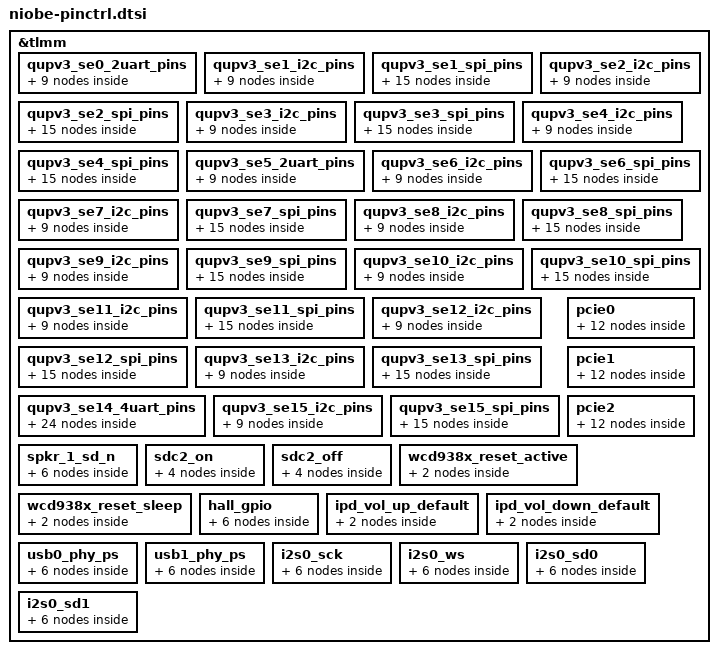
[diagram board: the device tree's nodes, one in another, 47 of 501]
&tlmm {
	qupv3_se0_2uart_pins: qupv3_se0_2uart_pins {
		qupv3_se0_2uart_tx_active: qupv3_se0_2uart_tx_active {
			mux {
				pins = "gpio54";
				function = "qup1_se0_l2";
			};

			config {
				pins = "gpio54";
				drive-strength = <2>;
				bias-disable;
			};
		};

		qupv3_se0_2uart_rx_active: qupv3_se0_2uart_rx_active {
			mux {
				pins = "gpio55";
				function = "qup1_se0_l3";
			};

			config {
				pins = "gpio55";
				drive-strength = <2>;
				bias-disable;
			};
		};

		qupv3_se0_2uart_sleep: qupv3_se0_2uart_sleep {
			mux {
				pins = "gpio54", "gpio55";
				function = "gpio";
			};

			config {
				pins = "gpio54", "gpio55";
				drive-strength = <2>;
				bias-pull-down;
			};
		};
	};

	qupv3_se1_i2c_pins: qupv3_se1_i2c_pins {
		qupv3_se1_i2c_sda_active: qupv3_se1_i2c_sda_active {
			mux {
				pins = "gpio56";
				function = "qup1_se1_l0";
			};

			config {
				pins = "gpio56";
				drive-strength = <2>;
				bias-pull-up;
			};
		};

		qupv3_se1_i2c_scl_active: qupv3_se1_i2c_scl_active {
			mux {
				pins = "gpio57";
				function = "qup1_se1_l1";
			};

			config {
				pins = "gpio57";
				drive-strength = <2>;
				bias-pull-up;
			};
		};

		qupv3_se1_i2c_sleep: qupv3_se1_i2c_sleep {
			mux {
				pins = "gpio56", "gpio57";
				function = "gpio";
			};

			config {
				pins = "gpio56", "gpio57";
				drive-strength = <2>;
				bias-disable;
			};
		};
	};

	qupv3_se1_spi_pins: qupv3_se1_spi_pins {
		qupv3_se1_spi_miso_active: qupv3_se1_spi_miso_active {
			mux {
				pins = "gpio56";
				function = "qup1_se1_l0";
			};

			config {
				pins = "gpio56";
				drive-strength = <6>;
				bias-disable;
			};
		};

		qupv3_se1_spi_mosi_active: qupv3_se1_spi_mosi_active {
			mux {
				pins = "gpio57";
				function = "qup1_se1_l1";
			};

			config {
				pins = "gpio57";
				drive-strength = <6>;
				bias-disable;
			};
		};

		qupv3_se1_spi_clk_active: qupv3_se1_spi_clk_active {
			mux {
				pins = "gpio58";
				function = "qup1_se1_l2";
			};

			config {
				pins = "gpio58";
				drive-strength = <6>;
				bias-disable;
			};
		};

		qupv3_se1_spi_cs_active: qupv3_se1_spi_cs_active {
			mux {
				pins = "gpio59";
				function = "qup1_se1_l3";
			};

			config {
				pins = "gpio59";
				drive-strength = <6>;
				bias-disable;
			};
		};

		qupv3_se1_spi_sleep: qupv3_se1_spi_sleep {
			mux {
				pins = "gpio56", "gpio57",
					"gpio58", "gpio59";
				function = "gpio";
			};

			config {
				pins = "gpio56", "gpio57",
					"gpio58", "gpio59";
				drive-strength = <2>;
				bias-disable;
			};
		};
	};

	qupv3_se2_i2c_pins: qupv3_se2_i2c_pins {
		qupv3_se2_i2c_sda_active: qupv3_se2_i2c_sda_active {
			mux {
				pins = "gpio63";
				function = "qup1_se2_l0";
			};

			config {
				pins = "gpio63";
				drive-strength = <2>;
				bias-pull-up;
			};
		};

		qupv3_se2_i2c_scl_active: qupv3_se2_i2c_scl_active {
			mux {
				pins = "gpio64";
				function = "qup1_se2_l1";
			};

			config {
				pins = "gpio64";
				drive-strength = <2>;
				bias-pull-up;
			};
		};

		qupv3_se2_i2c_sleep: qupv3_se2_i2c_sleep {
			mux {
				pins = "gpio63", "gpio64";
				function = "gpio";
			};

			config {
				pins = "gpio63", "gpio64";
				drive-strength = <2>;
				bias-disable;
			};
		};
	};

	qupv3_se2_spi_pins: qupv3_se2_spi_pins {
		qupv3_se2_spi_miso_active: qupv3_se2_spi_miso_active {
			mux {
				pins = "gpio63";
				function = "qup1_se2_l0";
			};

			config {
				pins = "gpio63";
				drive-strength = <6>;
				bias-disable;
			};
		};

		qupv3_se2_spi_mosi_active: qupv3_se2_spi_mosi_active {
			mux {
				pins = "gpio64";
				function = "qup1_se2_l1";
			};

			config {
				pins = "gpio64";
				drive-strength = <6>;
				bias-disable;
			};
		};

		qupv3_se2_spi_clk_active: qupv3_se2_spi_clk_active {
			mux {
				pins = "gpio65";
				function = "qup1_se2_l2";
			};

			config {
				pins = "gpio65";
				drive-strength = <6>;
				bias-disable;
			};
		};

		qupv3_se2_spi_cs_active: qupv3_se2_spi_cs_active {
			mux {
				pins = "gpio66";
				function = "qup1_se2_l3";
			};

			config {
				pins = "gpio66";
				drive-strength = <6>;
				bias-disable;
			};
		};

		qupv3_se2_spi_sleep: qupv3_se2_spi_sleep {
			mux {
				pins = "gpio63", "gpio64",
					"gpio65", "gpio66";
				function = "gpio";
			};

			config {
				pins = "gpio63", "gpio64",
					"gpio65", "gpio66";
				drive-strength = <2>;
				bias-disable;
			};
		};
	};

	qupv3_se3_i2c_pins: qupv3_se3_i2c_pins {
		qupv3_se3_i2c_sda_active: qupv3_se3_i2c_sda_active {
			mux {
				pins = "gpio67";
				function = "qup1_se3_l0";
			};

			config {
				pins = "gpio67";
				drive-strength = <2>;
				bias-pull-up;
			};
		};

		qupv3_se3_i2c_scl_active: qupv3_se3_i2c_scl_active {
			mux {
				pins = "gpio68";
				function = "qup1_se3_l1";
			};

			config {
				pins = "gpio68";
				drive-strength = <2>;
				bias-pull-up;
			};
		};

		qupv3_se3_i2c_sleep: qupv3_se3_i2c_sleep {
			mux {
				pins = "gpio67", "gpio68";
				function = "gpio";
			};

			config {
				pins = "gpio67", "gpio68";
				drive-strength = <2>;
				bias-disable;
			};
		};
	};

	qupv3_se3_spi_pins: qupv3_se3_spi_pins {
		qupv3_se3_spi_miso_active: qupv3_se3_spi_miso_active {
			mux {
				pins = "gpio67";
				function = "qup1_se3_l0";
			};

			config {
				pins = "gpio67";
				drive-strength = <6>;
				bias-disable;
			};
		};

		qupv3_se3_spi_mosi_active: qupv3_se3_spi_mosi_active {
			mux {
				pins = "gpio68";
				function = "qup1_se3_l1";
			};

			config {
				pins = "gpio68";
				drive-strength = <6>;
				bias-disable;
			};
		};

		qupv3_se3_spi_clk_active: qupv3_se3_spi_clk_active {
			mux {
				pins = "gpio69";
				function = "qup1_se3_l2";
			};

			config {
				pins = "gpio69";
				drive-strength = <6>;
				bias-disable;
			};
		};

		qupv3_se3_spi_cs_active: qupv3_se3_spi_cs_active {
			mux {
				pins = "gpio70";
				function = "qup1_se3_l3";
			};

			config {
				pins = "gpio70";
				drive-strength = <6>;
				bias-disable;
			};
		};

		qupv3_se3_spi_sleep: qupv3_se3_spi_sleep {
			mux {
				pins = "gpio67", "gpio68",
					"gpio69", "gpio70";
				function = "gpio";
			};

			config {
				pins = "gpio67", "gpio68",
					"gpio69", "gpio70";
				drive-strength = <2>;
				bias-disable;
			};
		};
	};

	qupv3_se4_i2c_pins: qupv3_se4_i2c_pins {
		qupv3_se4_i2c_sda_active: qupv3_se4_i2c_sda_active {
			mux {
				pins = "gpio0";
				function = "qup2_se0_l0";
			};

			config {
				pins = "gpio0";
				drive-strength = <2>;
				bias-pull-up;
			};
		};

		qupv3_se4_i2c_scl_active: qupv3_se4_i2c_scl_active {
			mux {
				pins = "gpio1";
				function = "qup2_se0_l1";
			};

			config {
				pins = "gpio1";
				drive-strength = <2>;
				bias-pull-up;
			};
		};

		qupv3_se4_i2c_sleep: qupv3_se4_i2c_sleep {
			mux {
				pins = "gpio0", "gpio1";
				function = "gpio";
			};

			config {
				pins = "gpio0", "gpio1";
				drive-strength = <2>;
				bias-disable;
			};
		};
	};

	qupv3_se4_spi_pins: qupv3_se4_spi_pins {
		qupv3_se4_spi_miso_active: qupv3_se4_spi_miso_active {
			mux {
				pins = "gpio0";
				function = "qup2_se0_l0";
			};

			config {
				pins = "gpio0";
				drive-strength = <6>;
				bias-disable;
			};
		};

		qupv3_se4_spi_mosi_active: qupv3_se4_spi_mosi_active {
			mux {
				pins = "gpio1";
				function = "qup2_se0_l1";
			};

			config {
				pins = "gpio1";
				drive-strength = <6>;
				bias-disable;
			};
		};

		qupv3_se4_spi_clk_active: qupv3_se4_spi_clk_active {
			mux {
				pins = "gpio2";
				function = "qup2_se0_l2";
			};

			config {
				pins = "gpio2";
				drive-strength = <6>;
				bias-disable;
			};
		};

		qupv3_se4_spi_cs_active: qupv3_se4_spi_cs_active {
			mux {
				pins = "gpio3";
				function = "qup2_se0_l3";
			};

			config {
				pins = "gpio3";
				drive-strength = <6>;
				bias-disable;
			};
		};

		qupv3_se4_spi_sleep: qupv3_se4_spi_sleep {
			mux {
				pins = "gpio0", "gpio1",
					"gpio2", "gpio3";
				function = "gpio";
			};

			config {
				pins = "gpio0", "gpio1",
					"gpio2", "gpio3";
				drive-strength = <2>;
				bias-disable;
			};
		};
	};

	qupv3_se5_2uart_pins: qupv3_se5_2uart_pins {
		qupv3_se5_2uart_tx_active: qupv3_se5_2uart_tx_active {
			mux {
				pins = "gpio6";
				function = "qup2_se1_l2";
			};

			config {
				pins = "gpio6";
				drive-strength = <2>;
				bias-disable;
			};
		};

		qupv3_se5_2uart_rx_active: qupv3_se5_2uart_rx_active {
			mux {
				pins = "gpio7";
				function = "qup2_se1_l3";
			};

			config {
				pins = "gpio7";
				drive-strength = <2>;
				bias-disable;
			};
		};

		qupv3_se5_2uart_sleep: qupv3_se5_2uart_sleep {
			mux {
				pins = "gpio6", "gpio7";
				function = "gpio";
			};

			config {
				pins = "gpio6", "gpio7";
				drive-strength = <2>;
				bias-pull-down;
			};
		};
	};

	qupv3_se6_i2c_pins: qupv3_se6_i2c_pins {
		qupv3_se6_i2c_sda_active: qupv3_se6_i2c_sda_active {
			mux {
				pins = "gpio8";
				function = "qup2_se2_l0";
			};

			config {
				pins = "gpio8";
				drive-strength = <2>;
				bias-pull-up;
			};
		};

		qupv3_se6_i2c_scl_active: qupv3_se6_i2c_scl_active {
			mux {
				pins = "gpio9";
				function = "qup2_se2_l1";
			};

			config {
				pins = "gpio9";
				drive-strength = <2>;
				bias-pull-up;
			};
		};

		qupv3_se6_i2c_sleep: qupv3_se6_i2c_sleep {
			mux {
				pins = "gpio8", "gpio9";
				function = "gpio";
			};

			config {
				pins = "gpio8", "gpio9";
				drive-strength = <2>;
				bias-disable;
			};
		};
	};

	qupv3_se6_spi_pins: qupv3_se6_spi_pins {
		qupv3_se6_spi_miso_active: qupv3_se6_spi_miso_active {
			mux {
				pins = "gpio8";
				function = "qup2_se2_l0";
			};

			config {
				pins = "gpio8";
				drive-strength = <6>;
				bias-disable;
			};
		};

		qupv3_se6_spi_mosi_active: qupv3_se6_spi_mosi_active {
			mux {
				pins = "gpio9";
				function = "qup2_se2_l1";
			};

			config {
				pins = "gpio9";
				drive-strength = <6>;
				bias-disable;
			};
		};

		qupv3_se6_spi_clk_active: qupv3_se6_spi_clk_active {
			mux {
				pins = "gpio10";
				function = "qup2_se2_l2";
			};

			config {
				pins = "gpio10";
				drive-strength = <6>;
				bias-disable;
			};
		};

		qupv3_se6_spi_cs_active: qupv3_se6_spi_cs_active {
			mux {
				pins = "gpio11";
				function = "qup2_se2_l3_mira";
			};

			config {
				pins = "gpio11";
				drive-strength = <6>;
				bias-disable;
			};
		};

		qupv3_se6_spi_sleep: qupv3_se6_spi_sleep {
			mux {
				pins = "gpio8", "gpio9",
					"gpio10", "gpio11";
				function = "gpio";
			};

			config {
				pins = "gpio8", "gpio9",
					"gpio10", "gpio11";
				drive-strength = <2>;
				bias-disable;
			};
		};
	};

	qupv3_se7_i2c_pins: qupv3_se7_i2c_pins {
		qupv3_se7_i2c_sda_active: qupv3_se7_i2c_sda_active {
			mux {
				pins = "gpio12";
				function = "qup2_se3_l0";
			};

			config {
				pins = "gpio12";
				drive-strength = <2>;
				bias-pull-up;
			};
		};

		qupv3_se7_i2c_scl_active: qupv3_se7_i2c_scl_active {
			mux {
				pins = "gpio13";
				function = "qup2_se3_l1";
			};

			config {
				pins = "gpio13";
				drive-strength = <2>;
				bias-pull-up;
			};
		};

		qupv3_se7_i2c_sleep: qupv3_se7_i2c_sleep {
			mux {
				pins = "gpio12", "gpio13";
				function = "gpio";
			};

			config {
				pins = "gpio12", "gpio13";
				drive-strength = <2>;
				bias-disable;
			};
		};
	};

	qupv3_se7_spi_pins: qupv3_se7_spi_pins {
		qupv3_se7_spi_miso_active: qupv3_se7_spi_miso_active {
			mux {
				pins = "gpio12";
				function = "qup2_se3_l0";
			};

			config {
				pins = "gpio12";
				drive-strength = <6>;
				bias-disable;
			};
		};

		qupv3_se7_spi_mosi_active: qupv3_se7_spi_mosi_active {
			mux {
				pins = "gpio13";
				function = "qup2_se3_l1";
			};

			config {
				pins = "gpio13";
				drive-strength = <6>;
				bias-disable;
			};
		};

		qupv3_se7_spi_clk_active: qupv3_se7_spi_clk_active {
			mux {
				pins = "gpio14";
				function = "qup2_se2_l2";
			};

			config {
				pins = "gpio14";
				drive-strength = <6>;
				bias-disable;
			};
		};

		qupv3_se7_spi_cs_active: qupv3_se7_spi_cs_active {
			mux {
				pins = "gpio15";
				function = "qup2_se3_l3";
			};

			config {
				pins = "gpio15";
				drive-strength = <6>;
				bias-disable;
			};
		};

		qupv3_se7_spi_sleep: qupv3_se7_spi_sleep {
			mux {
				pins = "gpio12", "gpio13",
					"gpio14", "gpio15";
				function = "gpio";
			};

			config {
				pins = "gpio12", "gpio13",
					"gpio14", "gpio15";
				drive-strength = <2>;
				bias-disable;
			};
		};
	};

	qupv3_se8_i2c_pins: qupv3_se8_i2c_pins {
		qupv3_se8_i2c_sda_active: qupv3_se8_i2c_sda_active {
			mux {
				pins = "gpio16";
				function = "qup2_se4_l0";
			};

			config {
				pins = "gpio16";
				drive-strength = <2>;
				bias-pull-up;
			};
		};

		qupv3_se8_i2c_scl_active: qupv3_se8_i2c_scl_active {
			mux {
				pins = "gpio17";
				function = "qup2_se4_l1";
			};

			config {
				pins = "gpio17";
				drive-strength = <2>;
				bias-pull-up;
			};
		};

		qupv3_se8_i2c_sleep: qupv3_se8_i2c_sleep {
			mux {
				pins = "gpio16", "gpio17";
				function = "gpio";
			};

			config {
				pins = "gpio16", "gpio17";
				drive-strength = <2>;
				bias-disable;
			};
		};
	};

	qupv3_se8_spi_pins: qupv3_se8_spi_pins {
		qupv3_se8_spi_miso_active: qupv3_se8_spi_miso_active {
			mux {
				pins = "gpio16";
				function = "qup2_se4_l0";
			};

			config {
				pins = "gpio16";
				drive-strength = <6>;
				bias-disable;
			};
		};

		qupv3_se8_spi_mosi_active: qupv3_se8_spi_mosi_active {
			mux {
				pins = "gpio17";
				function = "qup2_se4_l1";
			};

			config {
				pins = "gpio17";
				drive-strength = <6>;
				bias-disable;
			};
		};

		qupv3_se8_spi_clk_active: qupv3_se8_spi_clk_active {
			mux {
				pins = "gpio18";
				function = "qup2_se4_l2";
			};

			config {
				pins = "gpio18";
				drive-strength = <6>;
				bias-disable;
			};
		};

		qupv3_se8_spi_cs_active: qupv3_se8_spi_cs_active {
			mux {
				pins = "gpio19";
				function = "qup2_se4_l3";
			};

			config {
				pins = "gpio19";
				drive-strength = <6>;
				bias-disable;
			};
		};

		qupv3_se8_spi_sleep: qupv3_se8_spi_sleep {
			mux {
				pins = "gpio16", "gpio17",
					"gpio18", "gpio19";
				function = "gpio";
			};

			config {
				pins = "gpio16", "gpio17",
					"gpio18", "gpio19";
				drive-strength = <2>;
				bias-disable;
			};
		};
	};

	qupv3_se9_i2c_pins: qupv3_se9_i2c_pins {
		qupv3_se9_i2c_sda_active: qupv3_se9_i2c_sda_active {
			mux {
				pins = "gpio23";
				function = "qup2_se5_l0";
			};

			config {
				pins = "gpio23";
				drive-strength = <2>;
				bias-pull-up;
			};
		};

		qupv3_se9_i2c_scl_active: qupv3_se9_i2c_scl_active {
			mux {
				pins = "gpio24";
				function = "qup2_se5_l1";
			};

			config {
				pins = "gpio24";
				drive-strength = <2>;
				bias-pull-up;
			};
		};

		qupv3_se9_i2c_sleep: qupv3_se9_i2c_sleep {
			mux {
				pins = "gpio23", "gpio24";
				function = "gpio";
			};

			config {
				pins = "gpio23", "gpio24";
				drive-strength = <2>;
				bias-disable;
			};
		};
	};

	qupv3_se9_spi_pins: qupv3_se9_spi_pins {
		qupv3_se9_spi_miso_active: qupv3_se9_spi_miso_active {
			mux {
				pins = "gpio23";
				function = "qup2_se5_l0";
			};

			config {
				pins = "gpio23";
				drive-strength = <6>;
				bias-disable;
			};
		};

		qupv3_se9_spi_mosi_active: qupv3_se9_spi_mosi_active {
			mux {
				pins = "gpio24";
				function = "qup2_se5_l1";
			};

			config {
				pins = "gpio24";
				drive-strength = <6>;
				bias-disable;
			};
		};

		qupv3_se9_spi_clk_active: qupv3_se9_spi_clk_active {
			mux {
				pins = "gpio25";
				function = "qup2_se5_l2";
			};

			config {
				pins = "gpio25";
				drive-strength = <6>;
				bias-disable;
			};
		};

		qupv3_se9_spi_cs_active: qupv3_se9_spi_cs_active {
			mux {
				pins = "gpio26";
				function = "qup2_se5_l3_mira";
			};

			config {
				pins = "gpio26";
				drive-strength = <6>;
				bias-disable;
			};
		};

		qupv3_se9_spi_sleep: qupv3_se9_spi_sleep {
			mux {
				pins = "gpio23", "gpio24",
					"gpio25", "gpio26";
				function = "gpio";
			};

			config {
				pins = "gpio23", "gpio24",
					"gpio25", "gpio26";
				drive-strength = <2>;
				bias-disable;
			};
		};
	};

	qupv3_se10_i2c_pins: qupv3_se10_i2c_pins {
		qupv3_se10_i2c_sda_active: qupv3_se10_i2c_sda_active {
			mux {
				pins = "gpio27";
				function = "qup2_se6_l0";
			};

			config {
				pins = "gpio27";
				drive-strength = <2>;
				bias-pull-up;
			};
		};

		qupv3_se10_i2c_scl_active: qupv3_se10_i2c_scl_active {
			mux {
				pins = "gpio28";
				function = "qup2_se6_l1";
			};

			config {
				pins = "gpio28";
				drive-strength = <2>;
				bias-pull-up;
			};
		};

		qupv3_se10_i2c_sleep: qupv3_se10_i2c_sleep {
			mux {
				pins = "gpio27", "gpio28";
				function = "gpio";
			};

			config {
				pins = "gpio27", "gpio28";
				drive-strength = <2>;
				bias-disable;
			};
		};
	};

	qupv3_se10_spi_pins: qupv3_se10_spi_pins {
		qupv3_se10_spi_miso_active: qupv3_se10_spi_miso_active {
			mux {
				pins = "gpio27";
				function = "qup2_se6_l0";
			};

			config {
				pins = "gpio27";
				drive-strength = <6>;
				bias-disable;
			};
		};

		qupv3_se10_spi_mosi_active: qupv3_se10_spi_mosi_active {
			mux {
				pins = "gpio28";
				function = "qup2_se6_l1";
			};

			config {
				pins = "gpio28";
				drive-strength = <6>;
				bias-disable;
			};
		};

		qupv3_se10_spi_clk_active: qupv3_se10_spi_clk_active {
			mux {
				pins = "gpio29";
				function = "qup2_se6_l2";
			};

			config {
				pins = "gpio29";
				drive-strength = <6>;
				bias-disable;
			};
		};

		qupv3_se10_spi_cs_active: qupv3_se10_spi_cs_active {
			mux {
				pins = "gpio30";
				function = "qup2_se6_l3";
			};

			config {
				pins = "gpio30";
				drive-strength = <6>;
				bias-disable;
			};
		};

		qupv3_se10_spi_sleep: qupv3_se10_spi_sleep {
			mux {
				pins = "gpio27", "gpio28",
					"gpio29", "gpio30";
				function = "gpio";
			};

			config {
				pins = "gpio27", "gpio28",
					"gpio29", "gpio30";
				drive-strength = <2>;
				bias-disable;
			};
		};
	};

	qupv3_se11_i2c_pins: qupv3_se11_i2c_pins {
		qupv3_se11_i2c_sda_active: qupv3_se11_i2c_sda_active {
			mux {
				pins = "gpio31";
				function = "qup2_se7_l0";
			};

			config {
				pins = "gpio31";
				drive-strength = <2>;
				bias-pull-up;
			};
		};

		qupv3_se11_i2c_scl_active: qupv3_se11_i2c_scl_active {
			mux {
				pins = "gpio32";
				function = "qup2_se7_l1";
			};

			config {
				pins = "gpio32";
				drive-strength = <2>;
				bias-pull-up;
			};
		};

		qupv3_se11_i2c_sleep: qupv3_se11_i2c_sleep {
			mux {
				pins = "gpio31", "gpio32";
				function = "gpio";
			};

			config {
				pins = "gpio31", "gpio32";
				drive-strength = <2>;
				bias-disable;
			};
		};
	};

	qupv3_se11_spi_pins: qupv3_se11_spi_pins {
		qupv3_se11_spi_miso_active: qupv3_se11_spi_miso_active {
			mux {
				pins = "gpio31";
				function = "qup2_se7_l0";
			};

			config {
				pins = "gpio31";
				drive-strength = <6>;
				bias-disable;
			};
		};

		qupv3_se11_spi_mosi_active: qupv3_se11_spi_mosi_active {
			mux {
				pins = "gpio32";
				function = "qup2_se7_l1";
			};

			config {
				pins = "gpio32";
				drive-strength = <6>;
				bias-disable;
			};
		};

		qupv3_se11_spi_clk_active: qupv3_se11_spi_clk_active {
			mux {
				pins = "gpio33";
				function = "qup2_se7_l2";
			};

			config {
				pins = "gpio33";
				drive-strength = <6>;
				bias-disable;
			};
		};

		qupv3_se11_spi_cs_active: qupv3_se11_spi_cs_active {
			mux {
				pins = "gpio34";
				function = "qup2_se7_l3";
			};

			config {
				pins = "gpio34";
				drive-strength = <6>;
				bias-disable;
			};
		};

		qupv3_se11_spi_sleep: qupv3_se11_spi_sleep {
			mux {
				pins = "gpio31", "gpio32",
					"gpio33", "gpio34";
				function = "gpio";
			};

			config {
				pins = "gpio31", "gpio32",
					"gpio33", "gpio34";
				drive-strength = <2>;
				bias-disable;
			};
		};
	};

	qupv3_se12_i2c_pins: qupv3_se12_i2c_pins {
		qupv3_se12_i2c_sda_active: qupv3_se12_i2c_sda_active {
			mux {
				pins = "gpio40";
				function = "qup3_se0_l0";
			};

			config {
				pins = "gpio40";
				drive-strength = <2>;
				bias-pull-up;
			};
		};

		qupv3_se12_i2c_scl_active: qupv3_se12_i2c_scl_active {
			mux {
				pins = "gpio41";
				function = "qup3_se0_l1";
			};

			config {
				pins = "gpio41";
				drive-strength = <2>;
				bias-pull-up;
			};
		};

		qupv3_se12_i2c_sleep: qupv3_se12_i2c_sleep {
			mux {
				pins = "gpio40", "gpio41";
				function = "gpio";
			};

			config {
				pins = "gpio40", "gpio41";
				drive-strength = <2>;
				bias-disable;
			};
		};
	};

	qupv3_se12_spi_pins: qupv3_se12_spi_pins {
		qupv3_se12_spi_miso_active: qupv3_se12_spi_miso_active {
			mux {
				pins = "gpio40";
				function = "qup3_se0_l0";
			};

			config {
				pins = "gpio40";
				drive-strength = <6>;
				bias-disable;
			};
		};

		qupv3_se12_spi_mosi_active: qupv3_se12_spi_mosi_active {
			mux {
				pins = "gpio41";
				function = "qup3_se0_l1";
			};

			config {
				pins = "gpio41";
				drive-strength = <6>;
				bias-disable;
			};
		};

		qupv3_se12_spi_clk_active: qupv3_se12_spi_clk_active {
			mux {
				pins = "gpio42";
				function = "qup3_se0_l2";
			};

			config {
				pins = "gpio42";
				drive-strength = <6>;
				bias-disable;
			};
		};

		qupv3_se12_spi_cs_active: qupv3_se12_spi_cs_active {
			mux {
				pins = "gpio43";
				function = "qup3_se0_l3";
			};

			config {
				pins = "gpio43";
				drive-strength = <6>;
				bias-disable;
			};
		};

		qupv3_se12_spi_sleep: qupv3_se12_spi_sleep {
			mux {
				pins = "gpio40", "gpio41",
					"gpio42", "gpio43";
				function = "gpio";
			};

			config {
				pins = "gpio40", "gpio41",
					"gpio42", "gpio43";
				drive-strength = <2>;
				bias-disable;
			};
		};
	};

	qupv3_se13_i2c_pins: qupv3_se13_i2c_pins {
		qupv3_se13_i2c_sda_active: qupv3_se13_i2c_sda_active {
			mux {
				pins = "gpio36";
				function = "qup3_se1_l0";
			};

			config {
				pins = "gpio36";
				drive-strength = <2>;
				bias-pull-up;
			};
		};

		qupv3_se13_i2c_scl_active: qupv3_se13_i2c_scl_active {
			mux {
				pins = "gpio37";
				function = "qup3_se1_l1";
			};

			config {
				pins = "gpio37";
				drive-strength = <2>;
				bias-pull-up;
			};
		};

		qupv3_se13_i2c_sleep: qupv3_se13_i2c_sleep {
			mux {
				pins = "gpio36", "gpio37";
				function = "gpio";
			};

			config {
				pins = "gpio36", "gpio37";
				drive-strength = <2>;
				bias-disable;
			};
		};
	};

	qupv3_se13_spi_pins: qupv3_se13_spi_pins {
		qupv3_se13_spi_miso_active: qupv3_se13_spi_miso_active {
			mux {
				pins = "gpio36";
				function = "qup3_se1_l0";
			};

			config {
				pins = "gpio36";
				drive-strength = <6>;
				bias-disable;
			};
		};

		qupv3_se13_spi_mosi_active: qupv3_se13_spi_mosi_active {
			mux {
				pins = "gpio37";
				function = "qup3_se1_l1";
			};

			config {
				pins = "gpio37";
				drive-strength = <6>;
				bias-disable;
			};
		};

		qupv3_se13_spi_clk_active: qupv3_se13_spi_clk_active {
			mux {
				pins = "gpio38";
				function = "qup3_se1_l2";
			};

			config {
				pins = "gpio38";
				drive-strength = <6>;
				bias-disable;
			};
		};

		qupv3_se13_spi_cs_active: qupv3_se13_spi_cs_active {
			mux {
				pins = "gpio39";
				function = "qup3_se1_l3";
			};

			config {
				pins = "gpio39";
				drive-strength = <6>;
				bias-disable;
			};
		};

		qupv3_se13_spi_sleep: qupv3_se13_spi_sleep {
			mux {
				pins = "gpio36", "gpio37",
					"gpio38", "gpio39";
				function = "gpio";
			};

			config {
				pins = "gpio36", "gpio37",
					"gpio38", "gpio39";
				drive-strength = <2>;
				bias-disable;
			};
		};
	};

	qupv3_se14_4uart_pins: qupv3_se14_4uart_pins {
		qupv3_se14_default_cts: qupv3_se14_default_cts {
			mux {
				pins = "gpio44";
				function = "gpio";
			};

			config {
				pins = "gpio44";
				drive-strength = <2>;
				bias-disable;
			};
		};

		qupv3_se14_default_rts: qupv3_se14_default_rts {
			mux {
				pins = "gpio45";
				function = "gpio";
			};

			config {
				pins = "gpio45";
				drive-strength = <2>;
				bias-pull-down;
			};
		};

		qupv3_se14_default_tx: qupv3_se14_default_tx {
			mux {
				pins = "gpio46";
				function = "gpio";
			};

			config {
				pins = "gpio46";
				drive-strength = <2>;
				bias-pull-up;
			};
		};

		qupv3_se14_default_rx: qupv3_se14_default_rx {
			mux {
				pins = "gpio47";
				function = "gpio";
			};

			config {
				pins = "gpio47";
				drive-strength = <2>;
				bias-pull-down;
			};
		};

		qupv3_se14_cts: qupv3_se14_cts {
			mux {
				pins = "gpio44";
				function = "qup3_se2_l0";
			};

			config {
				pins = "gpio44";
				drive-strength = <2>;
				bias-disable;
			};
		};

		qupv3_se14_rts: qupv3_se14_rts {
			mux {
				pins = "gpio45";
				function = "qup3_se2_l1";
			};

			config {
				pins = "gpio45";
				drive-strength = <2>;
				bias-pull-down;
			};
		};

		qupv3_se14_tx: qupv3_se14_tx {
			mux {
				pins = "gpio46";
				function = "qup3_se2_l2";
			};

			config {
				pins = "gpio46";
				drive-strength = <2>;
				bias-pull-up;
			};
		};

		qupv3_se14_rx: qupv3_se14_rx {
			mux {
				pins = "gpio47";
				function = "qup3_se2_l3";
			};

			config {
				pins = "gpio47";
				drive-strength = <2>;
				bias-disable;
			};
		};
	};

	qupv3_se15_i2c_pins: qupv3_se15_i2c_pins {
		qupv3_se15_i2c_sda_active: qupv3_se15_i2c_sda_active {
			mux {
				pins = "gpio48";
				function = "qup3_se3_l0";
			};

			config {
				pins = "gpio48";
				drive-strength = <2>;
				bias-pull-up;
			};
		};

		qupv3_se15_i2c_scl_active: qupv3_se15_i2c_scl_active {
			mux {
				pins = "gpio49";
				function = "qup3_se3_l1";
			};

			config {
				pins = "gpio49";
				drive-strength = <2>;
				bias-pull-up;
			};
		};

		qupv3_se15_i2c_sleep: qupv3_se15_i2c_sleep {
			mux {
				pins = "gpio48", "gpio49";
				function = "gpio";
			};

			config {
				pins = "gpio48", "gpio49";
				drive-strength = <2>;
				bias-disable;
			};
		};
	};

	qupv3_se15_spi_pins: qupv3_se15_spi_pins {
		qupv3_se15_spi_miso_active: qupv3_se15_spi_miso_active {
			mux {
				pins = "gpio48";
				function = "qup3_se3_l0";
			};

			config {
				pins = "gpio48";
				drive-strength = <6>;
				bias-disable;
			};
		};

		qupv3_se15_spi_mosi_active: qupv3_se15_spi_mosi_active {
			mux {
				pins = "gpio49";
				function = "qup3_se3_l1";
			};

			config {
				pins = "gpio49";
				drive-strength = <6>;
				bias-disable;
			};
		};

		qupv3_se15_spi_clk_active: qupv3_se15_spi_clk_active {
			mux {
				pins = "gpio50";
				function = "qup3_se3_l2";
			};

			config {
				pins = "gpio50";
				drive-strength = <6>;
				bias-disable;
			};
		};

		qupv3_se15_spi_cs_active: qupv3_se15_spi_cs_active {
			mux {
				pins = "gpio51";
				function = "qup3_se3_l3";
			};

			config {
				pins = "gpio51";
				drive-strength = <6>;
				bias-disable;
			};
		};

		qupv3_se15_spi_sleep: qupv3_se15_spi_sleep {
			mux {
				pins = "gpio48", "gpio49",
					"gpio50", "gpio51";
				function = "gpio";
			};

			config {
				pins = "gpio48", "gpio49",
					"gpio50", "gpio51";
				drive-strength = <2>;
				bias-disable;
			};
		};
	};

	pcie0 {
		pcie0_perst_default: pcie0_perst_default {
			mux {
				pins = "gpio0";
				function = "gpio";
			};

			config {
				pins = "gpio0";
				drive-strength = <2>;
				bias-pull-down;
			};
		};

		pcie0_clkreq_default: pcie0_clkreq_default {
			mux {
				pins = "gpio126";
				function = "pcie0_clk_req_n";
			};

			config {
				pins = "gpio126";
				drive-strength = <2>;
				bias-pull-up;
			};
		};

		pcie0_wake_default: pcie0_wake_default {
			mux {
				pins = "gpio1";
				function = "gpio";
			};

			config {
				pins = "gpio1";
				drive-strength = <2>;
				bias-pull-up;
			};
		};

		pcie0_clkreq_sleep: pcie0_clkreq_sleep {
			mux {
				pins = "gpio126";
				function = "gpio";
			};

			config {
				pins = "gpio126";
				drive-strength = <2>;
				bias-pull-up;
				input-enable;
			};
		};
	};

	pcie1 {
		pcie1_perst_default: pcie1_perst_default {
			mux {
				pins = "gpio63";
				function = "gpio";
			};

			config {
				pins = "gpio63";
				drive-strength = <2>;
				bias-pull-down;
			};
		};

		pcie1_clkreq_default: pcie1_clkreq_default {
			mux {
				pins = "gpio139";
				function = "pcie1_clk_req_n";
			};

			config {
				pins = "gpio139";
				drive-strength = <2>;
				bias-pull-up;
			};
		};

		pcie1_wake_default: pcie1_wake_default {
			mux {
				pins = "gpio64";
				function = "gpio";
			};

			config {
				pins = "gpio64";
				drive-strength = <2>;
				bias-pull-up;
			};
		};

		pcie1_clkreq_sleep: pcie1_clkreq_sleep {
			mux {
				pins = "gpio139";
				function = "gpio";
			};

			config {
				pins = "gpio139";
				drive-strength = <2>;
				bias-pull-up;
			};
		};
	};

	pcie2 {
		pcie2_perst_default: pcie2_perst_default {
			mux {
				pins = "gpio67";
				function = "gpio";
			};

			config {
				pins = "gpio67";
				drive-strength = <2>;
				bias-pull-down;
			};
		};

		pcie2_clkreq_default: pcie2_clkreq_default {
			mux {
				pins = "gpio149";
				function = "pcie2_clk_req_n";
			};

			config {
				pins = "gpio149";
				drive-strength = <2>;
				bias-pull-up;
			};
		};

		pcie2_wake_default: pcie2_wake_default {
			mux {
				pins = "gpio71";
				function = "gpio";
			};

			config {
				pins = "gpio71";
				drive-strength = <2>;
				bias-pull-up;
			};
		};

		pcie2_clkreq_sleep: pcie2_clkreq_sleep {
			mux {
				pins = "gpio149";
				function = "gpio";
			};

			config {
				pins = "gpio149";
				drive-strength = <2>;
				bias-pull-up;
			};
		};
	};
	/* WSA speaker reset pins */
	spkr_1_sd_n {
		spkr_1_sd_n_sleep: spkr_1_sd_n_sleep {
			mux {
				pins = "gpio127";
				function = "gpio";
			};

			config {
				pins = "gpio127";
				drive-strength = <2>;   /* 2 mA */
				bias-pull-down;
				input-enable;
			};
		};

		spkr_1_sd_n_active: spkr_1_sd_n_active {
			mux {
				pins = "gpio127";
				function = "gpio";
			};

			config {
				pins = "gpio127";
				drive-strength = <16>;   /* 16 mA */
				bias-disable;
				output-high;
			};
		};
	};

	sdc2_on: sdc2_on {
		clk {
			pins = "gpio146";
			function = "sdc2_clk";
			bias-disable;
			drive-strength = <16>;
		};

		cmd {
			pins = "gpio145";
			function = "sdc2_cmd";
			bias-pull-up;
			drive-strength = <10>;
		};

		data {
			pins = "gpio141", "gpio142", "gpio143", "gpio144";
			function = "sdc2_data";
			bias-pull-up;
			drive-strength = <10>;
		};

		sd-cd {
			pins = "gpio148";
			bias-pull-up;
			drive-strength = <2>;
		};
	};

	sdc2_off: sdc2_off {
		clk {
			pins = "gpio146";
			function = "gpio";
			bias-disable;
			drive-strength = <2>;
		};

		cmd {
			pins = "gpio145";
			function = "gpio";
			bias-pull-up;
			drive-strength = <2>;
		};

		data {
			pins = "gpio141", "gpio142", "gpio143", "gpio144";
			function = "gpio";
			bias-pull-up;
			drive-strength = <2>;
		};

		sd-cd {
			pins = "gpio148";
			bias-pull-up;
			drive-strength = <2>;
		};
	};

	/* WCD reset pin */
	wcd938x_reset_active: wcd938x_reset_active {
		mux {
			pins = "gpio128";
			function = "gpio";
		};

		config {
			pins = "gpio128";
			drive-strength = <16>;
			output-high;
		};
	};

	wcd938x_reset_sleep: wcd938x_reset_sleep {
		mux {
			pins = "gpio128";
			function = "gpio";
		};

		config {
			pins = "gpio128";
			drive-strength = <16>;
			bias-disable;
			output-low;
		};
	};

	hall_gpio {
		hall_gpio_active: hall_gpio_active {
			mux {
				pins = "gpio12";
				function = "gpio";
			};

			config {
				pins = "gpio12";
				drive-strength = <2>;
				bias-pull-up;
				output-high;
			};
		};

		hall_gpio_sleep: hall_gpio_sleep {
			mux {
				pins = "gpio12";
				function = "gpio";
			};

			config {
				pins = "gpio12";
				drive-strength = <2>;
				bias-disable;
				output-low;
			};
		};
	};

	ipd_vol_up_default: ipd_vol_up_default {
		mux {
			pins = "gpio17";
			function = "gpio";
		};

		config {
			pins = "gpio17";
			bias-pull-up;
			drive-strength = <2>;
		};
	};

	ipd_vol_down_default: ipd_vol_down_default {
		mux {
			pins = "gpio16";
			function = "gpio";
		};

		config {
			pins = "gpio16";
			bias-pull-up;
			drive-strength = <2>;

		};
	};

	usb0_phy_ps: usb0_phy_ps {
		usb3_0_phy_portselect_default: usb3_0_phy_portselect_default {
			mux {
				pins = "gpio153";
				function = "USB0_PHY";
			};

			config {
				pins = "gpio153";
				bias-pull-down;
				drive-strength = <2>;
			};
		};

		usb3_0_phy_portselect_gpio: usb3_0_phy_portselect_gpio {
			mux {
				pins = "gpio153";
				function = "gpio";
			};

			config {
				pins = "gpio153";
				drive-strength = <2>;
				bias-pull-down;
				input-enable;
			};
		};
	};

	usb1_phy_ps: usb1_phy_ps {
		usb3_1_phy_portselect_default: usb3_1_phy_portselect_default {
			mux {
				pins = "gpio154";
				function = "USB1_PHY";
			};

			config {
				pins = "gpio154";
				bias-pull-down;
				drive-strength = <2>;
			};
		};

		usb3_1_phy_portselect_gpio: usb3_1_phy_portselect_gpio {
			mux {
				pins = "gpio154";
				function = "gpio";
			};

			config {
				pins = "gpio154";
				drive-strength = <2>;
				bias-pull-down;
				input-enable;
			};
		};
	};

	i2s0_sck {
		i2s0_sck_sleep: i2s0_sck_sleep {
			mux {
				pins = "gpio133";
				function = "gpio";
			};

			config {
				pins = "gpio133";
				drive-strength = <2>;   /* 2 mA */
				bias-pull-down;         /* PULL DOWN */
				input-enable;
			};
		};

		i2s0_sck_active: i2s0_sck_active {
			mux {
				pins = "gpio133";
				function = "i2s0_sck";
			};

			config {
				pins = "gpio133";
				drive-strength = <8>;   /* 8 mA */
				bias-disable;           /* NO PULL */
				output-high;
			};
		};
	};

	i2s0_ws {
		i2s0_ws_sleep: i2s0_ws_sleep {
			mux {
				pins = "gpio134";
				function = "gpio";
			};

			config {
				pins = "gpio134";
				drive-strength = <2>;   /* 2 mA */
				bias-pull-down;         /* PULL DOWN */
				input-enable;
			};
		};

		i2s0_ws_active: i2s0_ws_active {
			mux {
				pins = "gpio134";
				function = "i2s0_ws";
			};

			config {
				pins = "gpio134";
				drive-strength = <8>;   /* 8 mA */
				bias-disable;           /* NO PULL */
				output-high;
			};
		};
	};

	i2s0_sd0 {
		i2s0_sd0_sleep: i2s0_sd0_sleep {
			mux {
				pins = "gpio132";
				function = "gpio";
			};

			config {
				pins = "gpio132";
				drive-strength = <2>;   /* 2 mA */
				bias-pull-down;         /* PULL DOWN */
				input-enable;
			};
		};

		i2s0_sd0_active: i2s0_sd0_active {
			mux {
				pins = "gpio132";
				function = "i2s0_data0";
			};

			config {
				pins = "gpio132";
				drive-strength = <8>;   /* 8 mA */
				bias-disable;           /* NO PULL */
				output-high;
			};
		};
	};

	i2s0_sd1 {
		i2s0_sd1_sleep: i2s0_sd1_sleep {
			mux {
				pins = "gpio131";
				function = "gpio";
			};

			config {
				pins = "gpio131";
				drive-strength = <2>;   /* 2 mA */
				bias-pull-down;         /* PULL DOWN */
				input-enable;
			};
		};

		i2s0_sd1_active: i2s0_sd1_active {
			mux {
				pins = "gpio131";
				function = "i2s0_data1";
			};

			config {
				pins = "gpio131";
				drive-strength = <8>;   /* 8 mA */
				bias-disable;           /* NO PULL */
				output-high;
			};
		};
	};
};
